VERSION ""

NS_ :

BS_:

BU_: CANServer

BO_ 6 CANServer_Ehllo_Ack: 0 CANServer

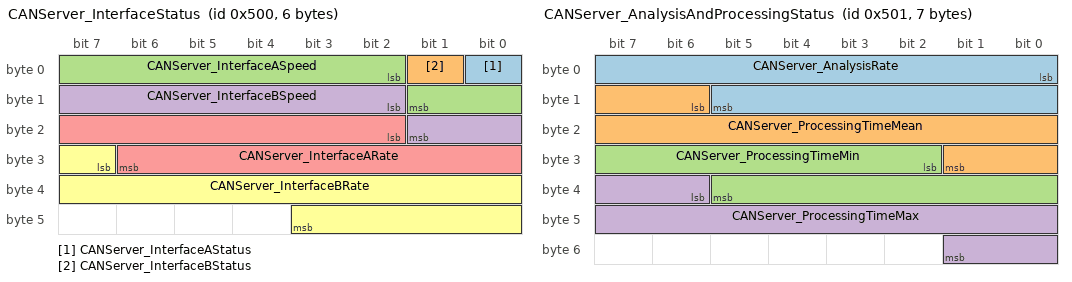
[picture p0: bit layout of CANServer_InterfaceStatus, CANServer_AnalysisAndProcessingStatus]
BO_ 1280 CANServer_InterfaceStatus: 6 CANServer
    SG_ CANServer_InterfaceAStatus : 0|1@1+ (1,0) [0|1] "" CANServer
    SG_ CANServer_InterfaceBStatus : 1|1@1+ (1,0) [0|1] "" CANServer
    SG_ CANServer_InterfaceASpeed : 2|8@1+ (5,0) [0|1000] "kbps" CANServer
    SG_ CANServer_InterfaceBSpeed : 10|8@1+ (5,0) [0|1000] "kbps" CANServer
    SG_ CANServer_InterfaceARate : 18|13@1+ (1,0) [0|8191] "frames/s" CANServer
    SG_ CANServer_InterfaceBRate : 31|13@1+ (1,0) [0|8191] "frames/s" CANServer

BO_ 1281 CANServer_AnalysisAndProcessingStatus: 7 CANServer
    SG_ CANServer_AnalysisRate : 0|14@1+ (1,0) [0|16383] "frames/s" CANServer
    SG_ CANServer_ProcessingTimeMean : 14|12@1+ (0.1,0) [0|409.5] "ms" CANServer
    SG_ CANServer_ProcessingTimeMin : 26|12@1+ (1,0) [0|4095] "ms" CANServer
    SG_ CANServer_ProcessingTimeMax : 38|12@1+ (1,0) [0|4095] "ms" CANServer

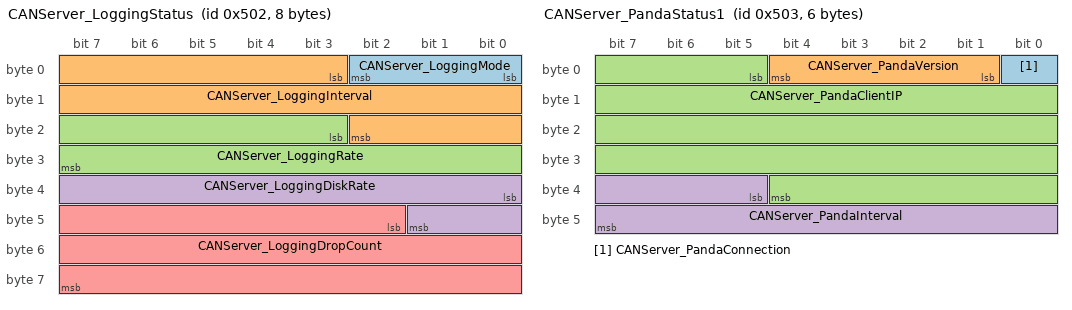
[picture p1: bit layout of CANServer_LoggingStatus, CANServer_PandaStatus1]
BO_ 1282 CANServer_LoggingStatus: 8 CANServer
    SG_ CANServer_LoggingMode : 0|3@1- (1,0) [-1|3] "" CANServer
    SG_ CANServer_LoggingInterval : 3|16@1+ (1,0) [0|65535] "ms" CANServer
    SG_ CANServer_LoggingRate : 19|13@1+ (1,0) [0|8191] "frames/s" CANServer
    SG_ CANServer_LoggingDiskRate : 32|10@1+ (0.1,0) [0|102.3] "KB/s" CANServer
    SG_ CANServer_LoggingDropCount : 42|22@1+ (1,0) [0|4194303] "frames" CANServer

BO_ 1283 CANServer_PandaStatus1: 6 CANServer
    SG_ CANServer_PandaConnection : 0|1@1+ (1,0) [0|1] "" CANServer
    SG_ CANServer_PandaVersion : 1|4@1+ (1,0) [0|15] "" CANServer
    SG_ CANServer_PandaClientIP : 5|32@1+ (1,0) [0|4294967295] "" CANServer
    SG_ CANServer_PandaInterval : 37|11@1+ (1,0) [0|2047] "ms" CANServer

BO_ 1284 CANServer_PandaStatus2: 4 CANServer
    SG_ CANServer_PandaRate : 0|13@1+ (1,0) [0|8191] "frames/s" CANServer
    SG_ CANServer_PandaNetRate : 13|12@1+ (0.1,0) [0|409.5] "KB/s" CANServer

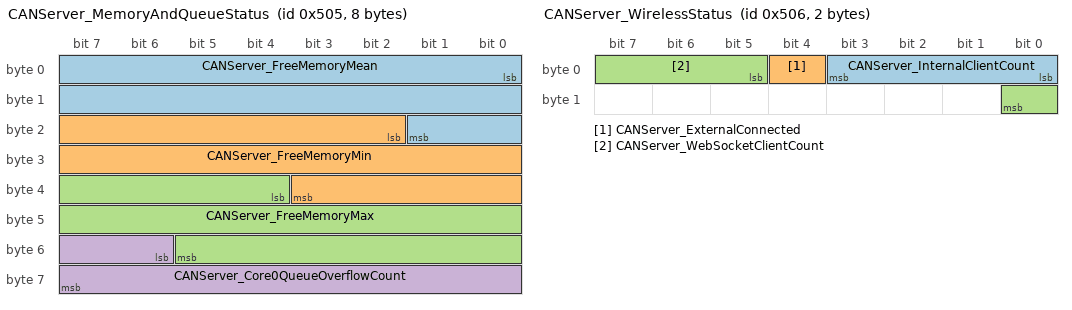
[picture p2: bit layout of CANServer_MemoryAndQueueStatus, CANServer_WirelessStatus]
BO_ 1285 CANServer_MemoryAndQueueStatus: 8 CANServer
    SG_ CANServer_FreeMemoryMean : 0|18@1+ (1,0) [0|262143] "bytes" CANServer
    SG_ CANServer_FreeMemoryMin : 18|18@1+ (1,0) [0|262143] "bytes" CANServer
    SG_ CANServer_FreeMemoryMax : 36|18@1+ (1,0) [0|262143] "bytes" CANServer
    SG_ CANServer_Core0QueueOverflowCount : 54|10@1+ (5,0) [0|1023] "frames" CANServer

BO_ 1286 CANServer_WirelessStatus: 2 CANServer
    SG_ CANServer_InternalClientCount : 0|4@1+ (1,0) [0|15] "" CANServer
    SG_ CANServer_ExternalConnected : 4|1@1+ (1,0) [0|1] "" CANServer
    SG_ CANServer_WebSocketClientCount : 5|4@1+ (1,0) [0|15] "" CANServer

BA_DEF_ BO_ "GenMsgBackgroundColor" STRING ;
BA_DEF_ BO_ "GenMsgForegroundColor" STRING ;
BA_ "GenMsgBackgroundColor" BO_ 1280 "#424242";
BA_DEF_DEF_ "GenMsgBackgroundColor" "#1e1e1e";
BA_DEF_DEF_ "GenMsgForegroundColor" "#ffffff";

VAL_ 1280 CANServer_InterfaceAStatus 1 "Enabled" 0 "Disabled";
VAL_ 1280 CANServer_InterfaceBStatus 1 "Enabled" 0 "Disabled";
VAL_ 1286 CANServer_ExternalConnected 1 "True" 0 "False";
VAL_ 1282 CANServer_LoggingMode -1 "Disabled" 0 "None" 1 "Raw" 2 "Interval" 3 "Filtered";
